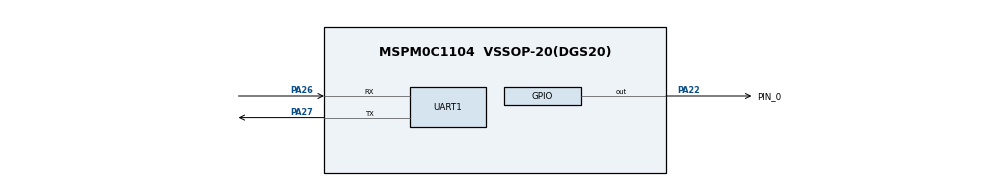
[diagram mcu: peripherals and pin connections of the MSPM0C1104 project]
//@cliArgs --device "MSPM0C110X" --package "VSSOP-20(DGS20)" --part "Default"
//@v2CliArgs --device "MSPM0C1104" --package "VSSOP-20(DGS20)"
// @cliArgs --board /ti/boards/LP_MSPM0C1104 --rtos nortos

/**
 * Import the modules used in this configuration.
 */
const GPIO          = scripting.addModule("/ti/driverlib/GPIO", {}, false);
const GPIO1         = GPIO.addInstance();
const GPIO2         = GPIO.addInstance();
const SYSCTL        = scripting.addModule("/ti/driverlib/SYSCTL");
const UART          = scripting.addModule("/ti/driverlib/UART", {}, false);
const UART1         = UART.addInstance();
const ProjectConfig = scripting.addModule("/ti/project_config/ProjectConfig");

/**
 * Write custom configuration values to the imported modules.
 */
GPIO1.$name                              = "GPIO_SWITCHES";
GPIO1.associatedPins[0].assignedPin      = "16";
GPIO1.associatedPins[0].$name            = "USER_SWITCH_1";
GPIO1.associatedPins[0].direction        = "INPUT";
GPIO1.associatedPins[0].internalResistor = "PULL_UP";
GPIO1.associatedPins[0].interruptEn      = true;
GPIO1.associatedPins[0].assignedPort     = "PORTA";
GPIO1.associatedPins[0].polarity         = "FALL";

const Board = scripting.addModule("/ti/driverlib/Board", {}, false);

GPIO2.$name                          = "GPIO_LED";
GPIO2.associatedPins[0].$name        = "PIN_0";
GPIO2.associatedPins[0].initialValue = "SET";
GPIO2.associatedPins[0].pin.$assign  = "PA22";

SYSCTL.clockTreeEn = true;

UART1.$name                        = "UART_0";
UART1.enabledInterrupts            = ["RX"];
UART1.peripheral.rxPin.$assign     = "PA26";
UART1.peripheral.txPin.$assign     = "PA27";
UART1.rxPinConfig.enableConfig     = true;
UART1.rxPinConfig.internalResistor = "PULL_UP";

ProjectConfig.genLinker  = false;
ProjectConfig.genStartup = false;
scripting.suppress("All four File Generation options must be enabled in order to guarantee Device Migration support\\. If an option is disabled, the user must manually configure that setting on its own file\\.", ProjectConfig);
